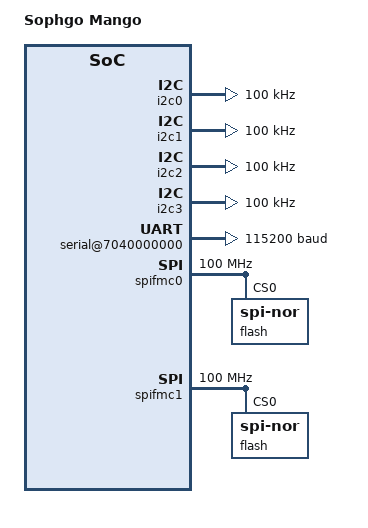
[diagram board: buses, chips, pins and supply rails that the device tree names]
/dts-v1/;

/ {
	model = "Sophgo Mango";
	compatible = "sophgo,mango";
	#address-cells = <2>;
	#size-cells = <2>;
	dma-noncoherent;

	cpus {
		#address-cells = <1>;
		#size-cells = <0>;
	};

	pmu {
		compatible = "riscv,pmu";
		riscv,event-to-mhpmevent =
			<0x00003 0x00000000 0x00000010>,
			<0x00004 0x00000000 0x00000011>,
			<0x00005 0x00000000 0x00000007>,
			<0x00006 0x00000000 0x00000006>,
			<0x00008 0x00000000 0x00000027>,
			<0x00009 0x00000000 0x00000028>,
			<0x10000 0x00000000 0x0000000c>,
			<0x10001 0x00000000 0x0000000d>,
			<0x10002 0x00000000 0x0000000e>,
			<0x10003 0x00000000 0x0000000f>,
			<0x10008 0x00000000 0x00000001>,
			<0x10009 0x00000000 0x00000002>,
			<0x10010 0x00000000 0x00000010>,
			<0x10011 0x00000000 0x00000011>,
			<0x10012 0x00000000 0x00000012>,
			<0x10013 0x00000000 0x00000013>,
			<0x10019 0x00000000 0x00000004>,
			<0x10021 0x00000000 0x00000003>,
			<0x10030 0x00000000 0x0000001c>,
			<0x10031 0x00000000 0x0000001b>;
		riscv,event-to-mhpmcounters =
			<0x00003 0x00003 0xfffffff8>,
			<0x00004 0x00004 0xfffffff8>,
			<0x00005 0x00005 0xfffffff8>,
			<0x00006 0x00006 0xfffffff8>,
			<0x00007 0x00007 0xfffffff8>,
			<0x00008 0x00008 0xfffffff8>,
			<0x00009 0x00009 0xfffffff8>,
			<0x0000a 0x0000a 0xfffffff8>,
			<0x10000 0x10000 0xfffffff8>,
			<0x10001 0x10001 0xfffffff8>,
			<0x10002 0x10002 0xfffffff8>,
			<0x10003 0x10003 0xfffffff8>,
			<0x10008 0x10008 0xfffffff8>,
			<0x10009 0x10009 0xfffffff8>,
			<0x10010 0x10010 0xfffffff8>,
			<0x10011 0x10011 0xfffffff8>,
			<0x10012 0x10012 0xfffffff8>,
			<0x10013 0x10013 0xfffffff8>,
			<0x10019 0x10019 0xfffffff8>,
			<0x10021 0x10021 0xfffffff8>,
			<0x10030 0x10030 0xfffffff8>,
			<0x10031 0x10031 0xfffffff8>;
		riscv,raw-event-to-mhpmcounters =
			<0x00000000 0x00000001 0xffffffff 0xffffffff 0xfffffff8>,
			<0x00000000 0x00000002 0xffffffff 0xffffffff 0xfffffff8>,
			<0x00000000 0x00000003 0xffffffff 0xffffffff 0xfffffff8>,
			<0x00000000 0x00000004 0xffffffff 0xffffffff 0xfffffff8>,
			<0x00000000 0x00000005 0xffffffff 0xffffffff 0xfffffff8>,
			<0x00000000 0x00000006 0xffffffff 0xffffffff 0xfffffff8>,
			<0x00000000 0x00000007 0xffffffff 0xffffffff 0xfffffff8>,
			<0x00000000 0x00000008 0xffffffff 0xffffffff 0xfffffff8>,
			<0x00000000 0x00000009 0xffffffff 0xffffffff 0xfffffff8>,
			<0x00000000 0x0000000a 0xffffffff 0xffffffff 0xfffffff8>,
			<0x00000000 0x0000000b 0xffffffff 0xffffffff 0xfffffff8>,
			<0x00000000 0x0000000c 0xffffffff 0xffffffff 0xfffffff8>,
			<0x00000000 0x0000000d 0xffffffff 0xffffffff 0xfffffff8>,
			<0x00000000 0x0000000e 0xffffffff 0xffffffff 0xfffffff8>,
			<0x00000000 0x0000000f 0xffffffff 0xffffffff 0xfffffff8>,
			<0x00000000 0x00000010 0xffffffff 0xffffffff 0xfffffff8>,
			<0x00000000 0x00000011 0xffffffff 0xffffffff 0xfffffff8>,
			<0x00000000 0x00000012 0xffffffff 0xffffffff 0xfffffff8>,
			<0x00000000 0x00000013 0xffffffff 0xffffffff 0xfffffff8>,
			<0x00000000 0x00000014 0xffffffff 0xffffffff 0xfffffff8>,
			<0x00000000 0x00000015 0xffffffff 0xffffffff 0xfffffff8>,
			<0x00000000 0x00000016 0xffffffff 0xffffffff 0xfffffff8>,
			<0x00000000 0x00000017 0xffffffff 0xffffffff 0xfffffff8>,
			<0x00000000 0x00000018 0xffffffff 0xffffffff 0xfffffff8>,
			<0x00000000 0x00000019 0xffffffff 0xffffffff 0xfffffff8>,
			<0x00000000 0x0000001a 0xffffffff 0xffffffff 0xfffffff8>,
			<0x00000000 0x0000001b 0xffffffff 0xffffffff 0xfffffff8>,
			<0x00000000 0x0000001c 0xffffffff 0xffffffff 0xfffffff8>,
			<0x00000000 0x0000001d 0xffffffff 0xffffffff 0xfffffff8>,
			<0x00000000 0x0000001e 0xffffffff 0xffffffff 0xfffffff8>,
			<0x00000000 0x0000001f 0xffffffff 0xffffffff 0xfffffff8>,
			<0x00000000 0x00000020 0xffffffff 0xffffffff 0xfffffff8>,
			<0x00000000 0x00000021 0xffffffff 0xffffffff 0xfffffff8>,
			<0x00000000 0x00000022 0xffffffff 0xffffffff 0xfffffff8>,
			<0x00000000 0x00000023 0xffffffff 0xffffffff 0xfffffff8>,
			<0x00000000 0x00000024 0xffffffff 0xffffffff 0xfffffff8>,
			<0x00000000 0x00000025 0xffffffff 0xffffffff 0xfffffff8>,
			<0x00000000 0x00000026 0xffffffff 0xffffffff 0xfffffff8>,
			<0x00000000 0x00000027 0xffffffff 0xffffffff 0xfffffff8>,
			<0x00000000 0x00000028 0xffffffff 0xffffffff 0xfffffff8>,
			<0x00000000 0x00000029 0xffffffff 0xffffffff 0xfffffff8>,
			<0x00000000 0x0000002a 0xffffffff 0xffffffff 0xfffffff8>;
	};

	soc: soc {
		#address-cells = <2>;
		#size-cells = <2>;
		compatible = "simple-bus";
		ranges;
		dma-ranges = <0x0 0x0 0x0 0x0 0x1f 0x0>;

		top_misc: top_misc_ctrl@7030010000 {
			compatible = "syscon";
			reg = <0x70 0x30010000 0x0 0x8000>;
		};

		i2c0: i2c@7030005000 {
			#address-cells = <1>;
			#size-cells = <0>;
			compatible = "snps,designware-i2c";
			reg = <0x70 0x30005000 0x0 0x1000>;
			clock-frequency = <100000>;
			alias = "i2c0";
		};

		i2c1: i2c@7030006000 {
			#address-cells = <1>;
			#size-cells = <0>;
			compatible = "snps,designware-i2c";
			reg = <0x70 0x30006000 0x0 0x1000>;
			clock-frequency = <100000>;
			alias = "i2c1";
		};

		i2c2: i2c@7030007000 {
			#address-cells = <1>;
			#size-cells = <0>;
			compatible = "snps,designware-i2c";
			reg = <0x70 0x30007000 0x0 0x1000>;
			clock-frequency = <100000>;
			alias = "i2c2";
		};

		i2c3: i2c@7030008000 {
			#address-cells = <1>;
			#size-cells = <0>;
			compatible = "snps,designware-i2c";
			reg = <0x70 0x30008000 0x0 0x1000>;
			clock-frequency = <100000>;
			alias = "i2c3";
		};

		gpio0: gpio@7030009000 {
			compatible = "snps,dw-apb-gpio";
			reg = <0x70 0x30009000 0x0 0x400>;
			#address-cells = <1>;
			#size-cells = <0>;
			alias = "gpio0";

			port0a: gpio-controller@0 {
				compatible = "snps,dw-apb-gpio-port";
				bank-name = "port0a";
				gpio-controller;
				#gpio-cells = <2>;
				snps,nr-gpios = <32>;
				reg = <0>;
			};
		};

		gpio1: gpio@703000a000 {
			compatible = "snps,dw-apb-gpio";
			reg = <0x70 0x3000a000 0x0 0x400>;
			#address-cells = <1>;
			#size-cells = <0>;
			alias = "gpio1";

			port1a: gpio-controller@0 {
				compatible = "snps,dw-apb-gpio-port";
				bank-name = "port0a";
				gpio-controller;
				#gpio-cells = <2>;
				snps,nr-gpios = <32>;
				reg = <0>;
			};
		};

		gpio2: gpio@703000b000 {
			compatible = "snps,dw-apb-gpio";
			reg = <0x70 0x3000b000 0x0 0x400>;
			#address-cells = <1>;
			#size-cells = <0>;
			alias = "gpio2";

			port2a: gpio-controller@0 {
				compatible = "snps,dw-apb-gpio-port";
				bank-name = "port0a";
				gpio-controller;
				#gpio-cells = <2>;
				snps,nr-gpios = <32>;
				reg = <0>;
			};
		};

		serial@7040000000 {
			compatible = "snps,dw-apb-uart";
			reg = <0x00000070 0x40000000 0x00000000 0x00001000>;
			clock-frequency = <500000000>;
			current-speed = <115200>;
			reg-shift = <2>;
			reg-io-width = <4>;
			stdio;
		};

		sd: bm-sd@704002b000 {
			compatible = "bitmain,bm-sd", "sophgo,sg2044-dwcmshc";
			reg = <0x70 0x4002B000 0x0 0x1000>;
			bus-width = <4>;
			alias = "sd0";
		};

		spifmc0: flash-controller@7000180000 {
			compatible = "sophgo,spifmc";
			reg = <0x70 0x00180000 0x0 0x1000000>;
			reg-names = "memory";
			#address-cells = <1>;
			#size-cells = <0>;
			clock-frequency = <100000000>;
			sophgo-config;
			alias = "flash0";
			flash@0 {
				reg = <0>;
				compatible = "jedec,spi-nor";
			};
		};

		spifmc1: flash-controller@7002180000 {
			compatible = "sophgo,spifmc";
			reg = <0x70 0x02180000 0x0 0x1000000>;
			reg-names = "memory";
			#address-cells = <1>;
			#size-cells = <0>;
			clock-frequency = <100000000>;
			sophgo-boot = <0x00000000 0x00600000>;
			alias = "flash1";
			flash@0 {
				reg = <0>;
				compatible = "jedec,spi-nor";
			};
		};
	};
};
